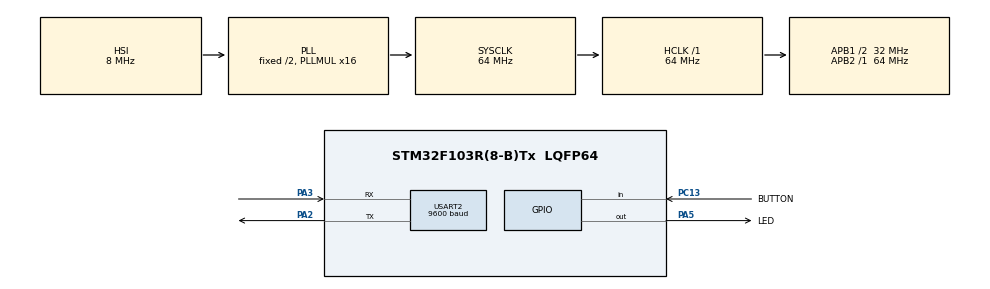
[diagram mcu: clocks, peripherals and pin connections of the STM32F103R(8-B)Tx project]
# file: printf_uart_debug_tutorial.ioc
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Mcu.Family=STM32F1
Mcu.Name=STM32F103R(8-B)Tx
Mcu.Package=LQFP64
NVIC.PriorityGroup=NVIC_PRIORITYGROUP_4
PA2.Mode=Asynchronous
PA2.Signal=USART2_TX
PA3.Mode=Asynchronous
PA3.Signal=USART2_RX
PA5.GPIO_Label=LED
PA5.Signal=GPIO_Output
PC13-TAMPER-RTC.GPIO_Label=BUTTON
PC13-TAMPER-RTC.Signal=GPIO_Input
ProjectManager.HeapSize=0x200
ProjectManager.StackSize=0x400
ProjectManager.TargetToolchain=MDK-ARM V5.27
RCC.AHBFreq_Value=64000000
RCC.APB1CLKDivider=RCC_HCLK_DIV2
RCC.APB1Freq_Value=32000000
RCC.APB1TimFreq_Value=64000000
RCC.APB2Freq_Value=64000000
RCC.APB2TimFreq_Value=64000000
RCC.HCLKFreq_Value=64000000
RCC.PLLMUL=RCC_PLL_MUL16
RCC.RTCClockSelection=RCC_RTCCLKSOURCE_LSE
RCC.SYSCLKFreq_VALUE=64000000
RCC.SYSCLKSource=RCC_SYSCLKSOURCE_PLLCLK
RCC.USBFreq_Value=64000000
USART2.BaudRate=9600
USART2.VirtualMode=VM_ASYNC
VP_SYS_VS_ND.Mode=No_Debug
board=NUCLEO-F103RB

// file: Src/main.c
/* USER CODE BEGIN Header */
/**
  ******************************************************************************
  * @file           : main.c
  * @brief          : Main program body
  ******************************************************************************
  * @attention
  *
  * <h2><center>&copy; Copyright (c) 2020 STMicroelectronics.
  * All rights reserved.</center></h2>
  *
  * This software component is licensed by ST under BSD 3-Clause license,
  * the "License"; You may not use this file except in compliance with the
  * License. You may obtain a copy of the License at:
  *                        opensource.org/licenses/BSD-3-Clause
  *
  ******************************************************************************
  */
/* USER CODE END Header */

#include "main.h"

/* USER CODE BEGIN Includes */
#include <stdio.h>
/* USER CODE END Includes */

/* USER CODE BEGIN PTD */
#ifdef __GNUC__
	/* With GCC, small printf (option LD Linker ->Libraries ->Small printf
		 set to 'Yes') calls __io_putchar() */
	#define PUTCHAR_PROTOTYPE int __io_putchar(int ch)
#else
	#define PUTCHAR_PROTOTYPE int fputc(int ch, FILE *f)
#endif
/* USER CODE END PTD */

UART_HandleTypeDef huart2;

void SystemClock_Config(void);
static void MX_GPIO_Init(void);
static void MX_USART2_UART_Init(void);

int main(void)
{
  /* USER CODE BEGIN 1 */
	int my_var = 0;
	float my_float = 0.0f;
  /* USER CODE END 1 */

  /* MCU Configuration--------------------------------------------------------*/

  /* Reset of all peripherals, Initializes the Flash interface and the Systick. */
  HAL_Init();

  /* Configure the system clock */
  SystemClock_Config();

  /* Initialize all configured peripherals */
  MX_GPIO_Init();
  MX_USART2_UART_Init();

  /* Infinite loop */
  while (1)
  {
		printf("Testing int = %d \r \n", my_var);
		my_var++;
		my_float += 1.21323;
		HAL_Delay(2000);
  }
}

void SystemClock_Config(void)
{
  RCC_OscInitTypeDef RCC_OscInitStruct = {0};
  RCC_ClkInitTypeDef RCC_ClkInitStruct = {0};

  /** Initializes the CPU, AHB and APB busses clocks
  */
  RCC_OscInitStruct.OscillatorType = RCC_OSCILLATORTYPE_HSI;
  RCC_OscInitStruct.HSIState = RCC_HSI_ON;
  RCC_OscInitStruct.HSICalibrationValue = RCC_HSICALIBRATION_DEFAULT;
  RCC_OscInitStruct.PLL.PLLState = RCC_PLL_ON;
  RCC_OscInitStruct.PLL.PLLSource = RCC_PLLSOURCE_HSI_DIV2;
  RCC_OscInitStruct.PLL.PLLMUL = RCC_PLL_MUL16;
  if (HAL_RCC_OscConfig(&RCC_OscInitStruct) != HAL_OK)
  {
    Error_Handler();
  }
  /** Initializes the CPU, AHB and APB busses clocks
  */
  RCC_ClkInitStruct.ClockType = RCC_CLOCKTYPE_HCLK|RCC_CLOCKTYPE_SYSCLK
                              |RCC_CLOCKTYPE_PCLK1|RCC_CLOCKTYPE_PCLK2;
  RCC_ClkInitStruct.SYSCLKSource = RCC_SYSCLKSOURCE_PLLCLK;
  RCC_ClkInitStruct.AHBCLKDivider = RCC_SYSCLK_DIV1;
  RCC_ClkInitStruct.APB1CLKDivider = RCC_HCLK_DIV2;
  RCC_ClkInitStruct.APB2CLKDivider = RCC_HCLK_DIV1;

  if (HAL_RCC_ClockConfig(&RCC_ClkInitStruct, FLASH_LATENCY_2) != HAL_OK)
  {
    Error_Handler();
  }
}

static void MX_USART2_UART_Init(void)
{

  huart2.Instance = USART2;
  huart2.Init.BaudRate = 9600;
  huart2.Init.WordLength = UART_WORDLENGTH_8B;
  huart2.Init.StopBits = UART_STOPBITS_1;
  huart2.Init.Parity = UART_PARITY_NONE;
  huart2.Init.Mode = UART_MODE_TX_RX;
  huart2.Init.HwFlowCtl = UART_HWCONTROL_NONE;
  huart2.Init.OverSampling = UART_OVERSAMPLING_16;
  if (HAL_UART_Init(&huart2) != HAL_OK)
  {
    Error_Handler();
  }

}

static void MX_GPIO_Init(void)
{
  GPIO_InitTypeDef GPIO_InitStruct = {0};

  /* GPIO Ports Clock Enable */
  __HAL_RCC_GPIOC_CLK_ENABLE();
  __HAL_RCC_GPIOA_CLK_ENABLE();

  /*Configure GPIO pin Output Level */
  HAL_GPIO_WritePin(LED_GPIO_Port, LED_Pin, GPIO_PIN_RESET);

  /*Configure GPIO pin : BUTTON_Pin */
  GPIO_InitStruct.Pin = BUTTON_Pin;
  GPIO_InitStruct.Mode = GPIO_MODE_INPUT;
  GPIO_InitStruct.Pull = GPIO_NOPULL;
  HAL_GPIO_Init(BUTTON_GPIO_Port, &GPIO_InitStruct);

  /*Configure GPIO pin : LED_Pin */
  GPIO_InitStruct.Pin = LED_Pin;
  GPIO_InitStruct.Mode = GPIO_MODE_OUTPUT_PP;
  GPIO_InitStruct.Pull = GPIO_NOPULL;
  GPIO_InitStruct.Speed = GPIO_SPEED_FREQ_LOW;
  HAL_GPIO_Init(LED_GPIO_Port, &GPIO_InitStruct);

}

/* USER CODE BEGIN 4 */
PUTCHAR_PROTOTYPE
{
	/* Place your implementation of fputc here */
	/* e.g. write a character to the EVAL_COM1 and Loop until the end of transmission */
	HAL_UART_Transmit(&huart2, (uint8_t *)&ch, 1, 0xFFFF);
	return ch;
}
/* USER CODE END 4 */

void Error_Handler(void)
{
}

/************************ (C) COPYRIGHT STMicroelectronics *****END OF FILE****/
